# STM32G563 register map
File version: 2.0.0
CPU: CM33 r0p4, little endian, MPU, FPU, 4 interrupt priority bits
Registers are 32-bit, read-write, reset 0x0 unless marked. A register's access mark holds for its fields unless they carry their own. Offsets are from the block's base; [hi:lo] are bit positions; {n}, {i} and the like mark numbered series; 'fields as' and 'values as' point back to an identical list.

## TAMP — TAMP register block
Base 0x44007C00
Same registers: TAMP_S 0x54007C00
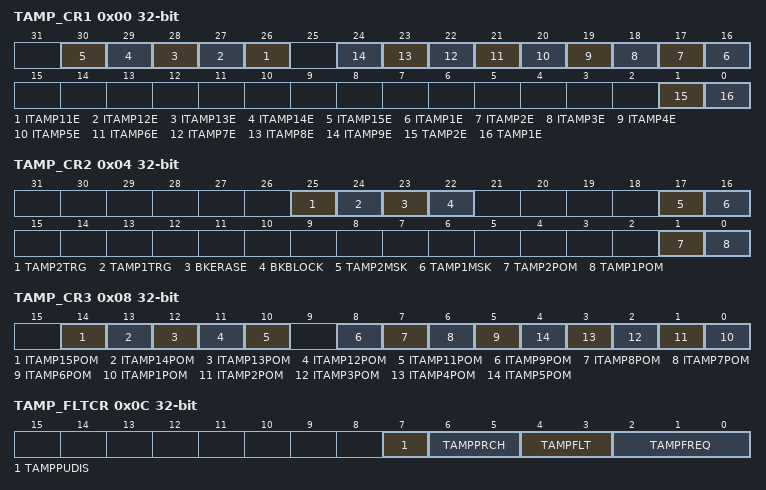
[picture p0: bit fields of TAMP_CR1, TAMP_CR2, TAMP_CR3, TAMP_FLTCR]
0x00 TAMP_CR1 — TAMP control register 1
  [n+15] ITAMP{n}E (n=11..15) — Internal tamper {n} enable
    0=Internal tamper {n} disabled; 1=Internal tamper {n} enabled
  [n+15] ITAMP{n}E (n=1..9) — Internal tamper {n} enable
    values as ITAMP11E
  [1] TAMP2E — Tamper detection on TAMP_IN2 enableless thansup>(1)less than/sup>
    0=Tamper detection on TAMP_IN2 is disabled; 1=Tamper detection on TAMP_IN2 is enabled
  [0] TAMP1E — Tamper detection on TAMP_IN1 enable
    0=Tamper detection on TAMP_IN1 is disabled; 1=Tamper detection on TAMP_IN1 is enabled
0x04 TAMP_CR2 — TAMP control register 2
  [25] TAMP2TRG — Active level for tamper 2 input
    0=If TAMPFLT different to 00 tamper 2 input staying low triggers a tamper detection event; 1=If TAMPFLT different to 00 tamper 2 input staying high triggers a tamper detection event
  [24] TAMP1TRG — Active level for tamper 1 input
    0=If TAMPFLT different to 00 tamper 1 input staying low triggers a tamper detection event; 1=If TAMPFLT different to 00 tamper 1 input staying high triggers a tamper detection event
  [23] BKERASE wo — Backup registers and device secretsless thansup>(1)less than/sup> erase
  [22] BKBLOCK — Backup registers and device secretsless thansup>(1)less than/sup> access blocked
    0=backup registers and device secretsless thansup>(1)less than/sup> can be accessed if no tamper flag is set; 1=backup registers and device secretsless thansup>(1)less than/sup> cannot be accessed
  [17] TAMP2MSK — Tamper 2 mask
    0=Tamper 2 event generates a trigger event and TAMP2F must be cleared by software to allow next tamper event detection; 1=Tamper 2 event generates a trigger event. TAMP2F is masked and internally cleared by hardware. The backup registers and device secretsless thansup>(1)less than/sup> are not erased.
  [16] TAMP1MSK — Tamper 1 mask
    0=Tamper 1 event generates a trigger event and TAMP1F must be cleared by software to allow next tamper event detection; 1=Tamper 1 event generates a trigger event. TAMP1F is masked and internally cleared by hardware. The backup registers and device secretsless thansup>(1)less than/sup> are not erased.
  [1] TAMP2POM — Tamper 2 potential mode
    0=Tamper 2 event detection is in confirmed modeless thansup>(1)less than/sup>; 1=Tamper 2 event detection is in potential modeless thansup>(2)less than/sup>
  [0] TAMP1POM — Tamper 1 potential mode
    0=Tamper 1 event detection is in confirmed mode; 1=Tamper 1 event detection is in potential mode
0x08 TAMP_CR3 — TAMP control register 3
  [14] ITAMP15POM — Internal tamper 15 potential mode
    0=Internal tamper 15 event detection is in confirmed modeless thansup>(1)less than/sup>; 1=Internal tamper 15 event detection is in potential modeless thansup>(2)less than/sup>
  [13] ITAMP14POM — Internal Tamper 14 potential mode
    0=Internal tamper 14 event detection is in confirmed modeless thansup>(1)less than/sup>; 1=Internal tamper 14 event detection is in potential modeless thansup>(2)less than/sup>
  [12] ITAMP13POM — Internal tamper 13 potential mode
    0=Internal tamper 13 event detection is in confirmed modeless thansup>(1)less than/sup>; 1=Internal tamper 13 event detection is in potential modeless thansup>(2)less than/sup>
  [11] ITAMP12POM — Internal tamper 12 potential mode
    0=Internal tamper 12 event detection is in confirmed modeless thansup>(1)less than/sup>; 1=Internal tamper 12 event detection is in potential modeless thansup>(2)less than/sup>
  [10] ITAMP11POM — Internal tamper 11 potential mode
    0=Internal tamper 11 event detection is in confirmed modeless thansup>(1)less than/sup>; 1=Internal tamper 11 event detection is in potential modeless thansup>(2)less than/sup>
  [8] ITAMP9POM — Internal tamper 9 potential mode
    0=Internal tamper 9 event detection is in confirmed modeless thansup>(1)less than/sup>; 1=Internal tamper 9 event detection is in potential modeless thansup>(2)less than/sup>
  [7] ITAMP8POM — Internal tamper 8 potential mode
    0=Internal tamper 8 event detection is in confirmed modeless thansup>(1)less than/sup>; 1=Internal tamper 8 event detection is in potential modeless thansup>(2)less than/sup>
  [6] ITAMP7POM — Internal tamper 7 potential mode
    0=Internal tamper 7 event detection is in confirmed modeless thansup>(1)less than/sup>; 1=Internal tamper 7 event detection is in potential modeless thansup>(2)less than/sup>
  [5] ITAMP6POM — Internal tamper 6 potential mode
    0=Internal tamper 6 event detection is in confirmed mode; 1=Internal tamper 6 event detection is in potential mode
  [n-1] ITAMP{n}POM (n=1..5) — Internal tamper {n} potential mode
    0=Internal tamper {n} event detection is in confirmed modeless thansup>(1)less than/sup>; 1=Internal tamper {n} event detection is in potential modeless thansup>(2)less than/sup>
0x0C TAMP_FLTCR — TAMP filter control register
  [7] TAMPPUDIS — TAMP_INx pull-up disable
    0=Precharge TAMP_INx pins before sampling (enable internal pull-up); 1=Disable precharge of TAMP_INx pins
  [6:5] TAMPPRCH — TAMP_INx precharge duration
    0=1 RTCCLK cycle; 1=2 RTCCLK cycles; 2=4 RTCCLK cycles; 3=8 RTCCLK cycles
  [4:3] TAMPFLT — TAMP_INx filter count
    0=Tamper event is activated on edge of TAMP_INx input transitions to the active level (no internal pull-up on TAMP_INx input); 1=Tamper event is activated after 2 consecutive samples at the active level; 2=Tamper event is activated after 4 consecutive samples at the active level; 3=Tamper event is activated after 8 consecutive samples at the active level
  [2:0] TAMPFREQ — Tamper sampling frequency
    0=RTCCLK / 32768 (1Hz when RTCCLK = 32768Hz); 1=RTCCLK / 16384 (2Hz when RTCCLK = 32768Hz); 2=RTCCLK / 8192 (4Hz when RTCCLK = 32768Hz); 3=RTCCLK / 4096 (8Hz when RTCCLK = 32768Hz); 4=RTCCLK / 2048 (16Hz when RTCCLK = 32768Hz); 5=RTCCLK / 1024 (32Hz when RTCCLK = 32768Hz); 6=RTCCLK / 512 (64Hz when RTCCLK = 32768Hz); 7=RTCCLK / 256 (128Hz when RTCCLK = 32768Hz)
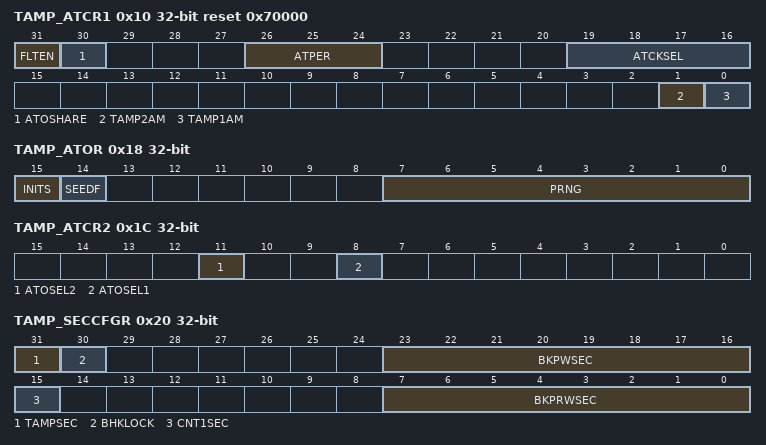
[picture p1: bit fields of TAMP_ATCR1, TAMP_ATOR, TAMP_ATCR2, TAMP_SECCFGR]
0x10 TAMP_ATCR1 reset 0x70000 — TAMP active tamper control register 1
  [31] FLTEN — Active tamper filter enable
    0=Active tamper filtering disable; 1=Active tamper filtering enable: a tamper event is detected when 2 comparison mismatches occur out of 4 consecutive samples
  [30] ATOSHARE — Active tamper output sharing
    0=Each active tamper input TAMP_INi is compared with its dedicated output TAMP_OUTi; 1=Each active tamper input TAMP_INi is compared with TAMPOUTSELi defined by ATOSELi bits
  [26:24] ATPER — Active tamper output change period
  [19:16] ATCKSEL — Active tamper RTC asynchronous prescaler clock selection
  [1] TAMP2AM — Tamper 2 active mode
    0=Tamper 2 detection mode is passive; 1=Tamper 2 detection mode is active
  [0] TAMP1AM — Tamper 1 active mode
    0=Tamper 1 detection mode is passive; 1=Tamper 1 detection mode is active
0x14 TAMP_ATSEEDR wo — TAMP active tamper seed register
  [31:0] SEED — Pseudo-random generator seed value
0x18 TAMP_ATOR ro — TAMP active tamper output register
  [15] INITS — Active tamper initialization status
  [14] SEEDF — Seed running flag
  [7:0] PRNG — Pseudo-random generator value
0x1C TAMP_ATCR2 — TAMP active tamper control register 2
  [11] ATOSEL2 — Active tamper shared output 2 selection
    0=TAMPOUTSEL2 = TAMP_OUT1; 1=TAMPOUTSEL2 = TAMP_OUT2
  [8] ATOSEL1 — Active tamper shared output 1 selection
    0=TAMPOUTSEL1 = TAMP_OUT1; 1=TAMPOUTSEL1 = TAMP_OUT2
0x20 TAMP_SECCFGR — TAMP secure configuration register
  [31] TAMPSEC — Tamper protection (excluding monotonic counters and backup registers)
    0=Tamper configuration and interrupt can be written when the APB access is secure or nonsecure; 1=Tamper configuration and interrupt can be written only when the APB access is secure
  [30] BHKLOCK — Boot hardware key lock
    0=The Backup registers from TAMP_BKP0R to TAMP_BKP7R can be accessed according to the Protection zone they belong to; 1=The backup registers from TAMP_BKP0R to TAMP_BKP7R cannot be accessed neither in read nor in write (they are read as 0 and write ignore)
  [23:16] BKPWSEC — Backup registers write protection offset
  [15] CNT1SEC — Monotonic counter 1 secure protection
    0=Monotonic counter 1 (TAMP_COUNT1R) can be read and written when the APB access is secure or nonsecure; 1=Monotonic counter 1 (TAMP_COUNT1R) can be read and written only when the APB access is secure
  [7:0] BKPRWSEC — Backup registers read/write protection offset
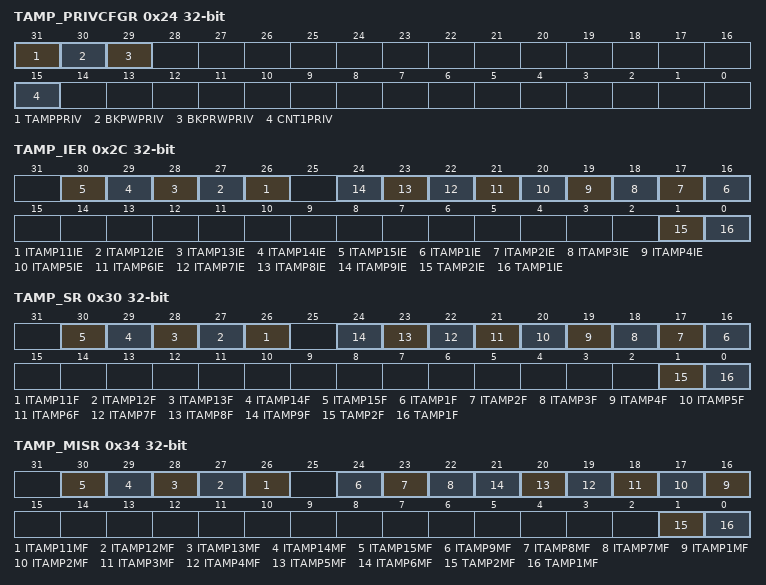
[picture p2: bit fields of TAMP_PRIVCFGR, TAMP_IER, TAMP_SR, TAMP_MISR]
0x24 TAMP_PRIVCFGR — TAMP privilege configuration register
  [31] TAMPPRIV — Tamper privilege protection (excluding backup registers)
    0=Tamper configuration and interrupt can be written with privileged or unprivileged access; 1=Tamper configuration and interrupt can be written only with privileged access
  [30] BKPWPRIV — Backup registers zone 2 privilege protection
    0=Backup registers zone 2 can be written with privileged or unprivileged access; 1=Backup registers zone 2 can be written only with privileged access
  [29] BKPRWPRIV — Backup registers zone 1 privilege protection
    0=Backup registers zone 1 can be read and written with privileged or unprivileged access; 1=Backup registers zone 1 can be read and written only with privileged access
  [15] CNT1PRIV — Monotonic counter 1 privilege protection
    0=Monotonic counter 1 (TAMP_COUNT1R) can be read and written when the APB access is privileged or non-privileged; 1=Monotonic counter 1 (TAMP_COUNT1R) can be read and written only when the APB access is privileged
0x2C TAMP_IER — TAMP interrupt enable register
  [n+15] ITAMP{n}IE (n=11..15) — Internal tamper {n} interrupt enable
    0=Internal tamper {n} interrupt disabled; 1=Internal tamper {n} interrupt enabled
  [n+15] ITAMP{n}IE (n=1..9) — Internal tamper {n} interrupt enable
    values as ITAMP11IE
  [1] TAMP2IE — Tamper 2 interrupt enable
    0=Tamper 2 interrupt disabled; 1=Tamper 2 interrupt enabled
  [0] TAMP1IE — Tamper 1 interrupt enable
    0=Tamper 1 interrupt disabled; 1=Tamper 1 interrupt enabled
0x30 TAMP_SR ro — TAMP status register
  [n+15] ITAMP{n}F (n=11..15) — Internal tamper {n} flag
  [n+15] ITAMP{n}F (n=1..9) — Internal tamper {n} flag
  [1] TAMP2F — TAMP2 detection flag
  [0] TAMP1F — TAMP1 detection flag
0x34 TAMP_MISR ro — TAMP nonsecure masked interrupt status register
  [n+15] ITAMP{n}MF (n=11..15) — internal tamper {n} nonsecure interrupt masked flag
  [24] ITAMP9MF — internal tamper 9 nonsecure interrupt masked flag
  [23] ITAMP8MF — Internal tamper 8 nonsecure interrupt masked flag
  [22] ITAMP7MF — Internal tamper 7 tamper nonsecure interrupt masked flag
  [n+15] ITAMP{n}MF (n=1..6) — Internal tamper {n} nonsecure interrupt masked flag
  [1] TAMP2MF — TAMP2 nonsecure interrupt masked flag
  [0] TAMP1MF — TAMP1 nonsecure interrupt masked flag
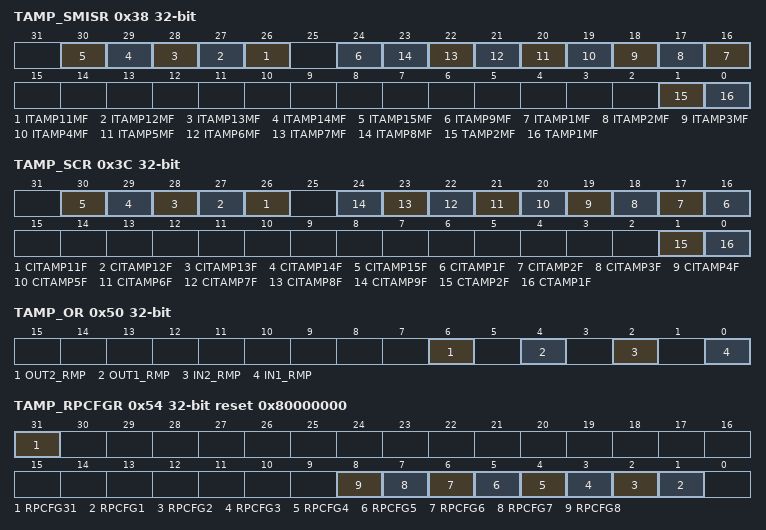
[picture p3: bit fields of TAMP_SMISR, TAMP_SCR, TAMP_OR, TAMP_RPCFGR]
0x38 TAMP_SMISR ro — TAMP secure masked interrupt status register
  [n+15] ITAMP{n}MF (n=11..15) — internal tamper {n} secure interrupt masked flag
  [24] ITAMP9MF — internal tamper 9 secure interrupt masked flag
  [n+15] ITAMP{n}MF (n=1..8) — Internal tamper {n} secure interrupt masked flag
  [1] TAMP2MF — TAMP2 secure interrupt masked flag
  [0] TAMP1MF — TAMP1 secure interrupt masked flag
0x3C TAMP_SCR wo — TAMP status clear register
  [n+15] CITAMP{n}F (n=11..15) — Clear ITAMP{n} detection flag
  [n+15] CITAMP{n}F (n=1..9) — Clear ITAMP{n} detection flag
  [1] CTAMP2F — Clear TAMP2 detection flag
  [0] CTAMP1F — Clear TAMP1 detection flag
0x40 TAMP_COUNT1R ro — TAMP monotonic counter 1 register
  [31:0] COUNT — This register is read-only only and is incremented by one when a write access is done to this register. This register cannot roll-over and is frozen when reaching the maximum value.
0x50 TAMP_OR — TAMP option register
  [6] OUT2_RMP — TAMP_OUT2 mapping
    0=TAMP_OUT2 is mapped on PB9; 1=TAMP_OUT2 is mapped on PE3
  [4] OUT1_RMP — TAMP_OUT1 mapping
    0=TAMP_OUT1 is mapped on PA2; 1=TAMP_OUT1 is mapped on PC13
  [2] IN2_RMP — TAMP_IN2 mapping
    0=TAMP_IN2 is mapped on PA1; 1=TAMP_IN2 is mapped on PC13
  [0] IN1_RMP — TAMP_IN1 mapping
    0=TAMP_IN1 is mapped on PA0; 1=TAMP_IN1 is mapped on PB9
0x54 TAMP_RPCFGR reset 0x80000000 — TAMP resources protection configuration register
  [31] RPCFG31 — Backup registers protection
    0=Backup registers and BHKLOCK are not included in the device secrets protected by TAMP peripheral; 1=Backup registers and BHKLOCK are included in the device secrets protected by TAMP peripheral
  [n] RPCFG{n} (n=1..8) — Configurable resource {n} protection
    0=Resource {n} is not included in the device secrets protected by TAMP peripheral; 1=Resource {n} is included in the device secrets protected by TAMP peripheral
{0x100+4i} TAMP_BKP{i}R (i=0..31) — TAMP backup {i} register
  [31:0] BKP — The application can write or read data to and from these registers.
